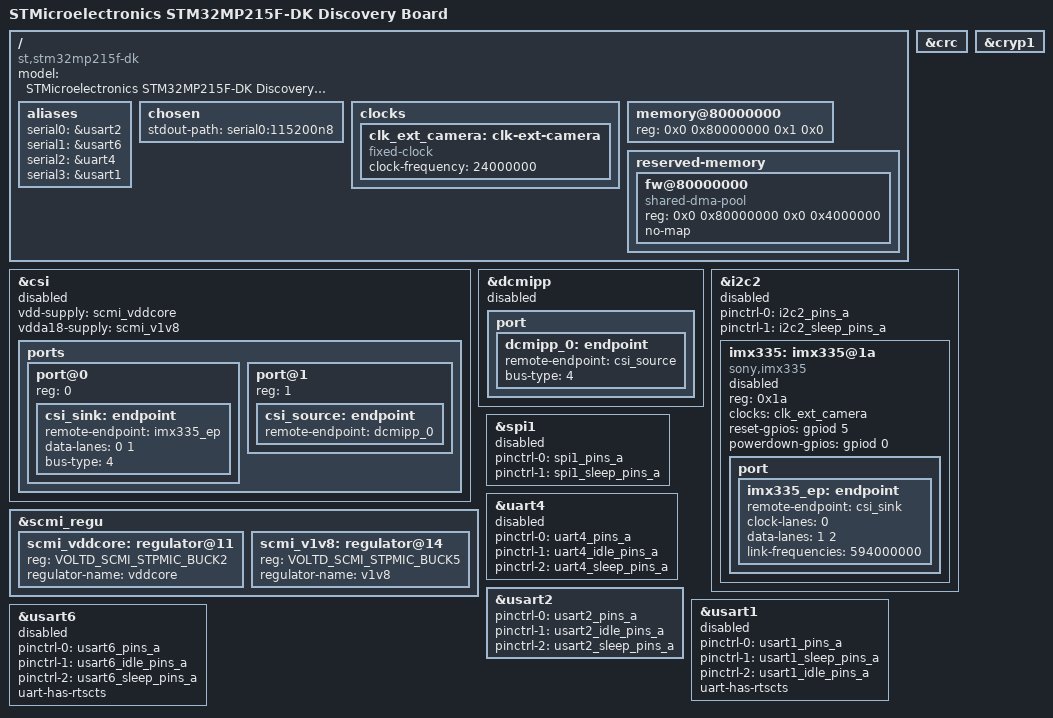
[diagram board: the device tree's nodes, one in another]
// SPDX-License-Identifier: (GPL-2.0-only OR BSD-3-Clause)
/*
 * Copyright (C) STMicroelectronics 2024 - All Rights Reserved
 * Author: Amelie Delaunay <amelie.delaunay@foss.st.com> for STMicroelectronics.
 */

/dts-v1/;

#include <dt-bindings/gpio/gpio.h>
#include "stm32mp215.dtsi"
#include "stm32mp21xf.dtsi"
#include "stm32mp21-pinctrl.dtsi"
#include "stm32mp21xxan-pinctrl.dtsi"

/ {
	model = "STMicroelectronics STM32MP215F-DK Discovery Board";
	compatible = "st,stm32mp215f-dk", "st,stm32mp215";

	aliases {
		serial0 = &usart2;
		serial1 = &usart6;
		serial2 = &uart4;
		serial3 = &usart1;
	};

	chosen {
		stdout-path = "serial0:115200n8";
	};

	clocks {
		clk_ext_camera: clk-ext-camera {
			#clock-cells = <0>;
			compatible = "fixed-clock";
			clock-frequency = <24000000>;
		};
	};

	memory@80000000 {
		device_type = "memory";
		reg = <0x0 0x80000000 0x1 0x0>;
	};

	reserved-memory {
		#address-cells = <2>;
		#size-cells = <2>;
		ranges;

		fw@80000000 {
			compatible = "shared-dma-pool";
			reg = <0x0 0x80000000 0x0 0x4000000>;
			no-map;
		};
	};
};

&crc {
	status = "okay";
};

&cryp1 {
	status = "okay";
};

&csi {
	vdd-supply =  <&scmi_vddcore>;
	vdda18-supply = <&scmi_v1v8>;
	status = "disabled";
	ports {
		#address-cells = <1>;
		#size-cells = <0>;
		port@0 {
			reg = <0>;
			csi_sink: endpoint {
				remote-endpoint = <&imx335_ep>;
				data-lanes = <0 1>;
				bus-type = <4>;
			};
		};
		port@1 {
			reg = <1>;
			csi_source: endpoint {
				remote-endpoint = <&dcmipp_0>;
			};
		};
	};
};

&dcmipp {
	status = "disabled";
	port {
		dcmipp_0: endpoint {
			remote-endpoint = <&csi_source>;
			bus-type = <4>;
		};
	};
};

&i2c2 {
	pinctrl-names = "default", "sleep";
	pinctrl-0 = <&i2c2_pins_a>;
	pinctrl-1 = <&i2c2_sleep_pins_a>;
	status = "disabled";

	imx335: imx335@1a {
		compatible = "sony,imx335";
		reg = <0x1a>;
		clocks = <&clk_ext_camera>;
		reset-gpios = <&gpiod 5 (GPIO_ACTIVE_HIGH | GPIO_PUSH_PULL)>;
		powerdown-gpios = <&gpiod 0 (GPIO_ACTIVE_HIGH | GPIO_PUSH_PULL)>;
		status = "disabled";

		port {
			imx335_ep: endpoint {
				remote-endpoint = <&csi_sink>;
				clock-lanes = <0>;
				data-lanes = <1 2>;
				link-frequencies = /bits/ 64 <594000000>;
			};
		};
	};
};

&scmi_regu {
	scmi_vddcore: regulator@11  {
		reg = <VOLTD_SCMI_STPMIC_BUCK2>;
		regulator-name = "vddcore";
	};
	scmi_v1v8: regulator@14  {
		reg = <VOLTD_SCMI_STPMIC_BUCK5>;
		regulator-name = "v1v8";
	};
};

&spi1 {
	pinctrl-names = "default", "sleep";
	pinctrl-0 = <&spi1_pins_a>;
	pinctrl-1 = <&spi1_sleep_pins_a>;
	status = "disabled";
};

&uart4 {
	pinctrl-names = "default", "idle", "sleep";
	pinctrl-0 = <&uart4_pins_a>;
	pinctrl-1 = <&uart4_idle_pins_a>;
	pinctrl-2 = <&uart4_sleep_pins_a>;
	/delete-property/dmas;
	/delete-property/dma-names;
	status = "disabled";
};

&usart2 {
	pinctrl-names = "default", "idle", "sleep";
	pinctrl-0 = <&usart2_pins_a>;
	pinctrl-1 = <&usart2_idle_pins_a>;
	pinctrl-2 = <&usart2_sleep_pins_a>;
	/delete-property/dmas;
	/delete-property/dma-names;
	status = "okay";
};

/* Bluetooth */
&usart1 {
	pinctrl-names = "default", "sleep", "idle";
	pinctrl-0 = <&usart1_pins_a>;
	pinctrl-1 = <&usart1_sleep_pins_a>;
	pinctrl-2 = <&usart1_idle_pins_a>;
	uart-has-rtscts;
	status = "disabled";
};

&usart6 {
	pinctrl-names = "default", "idle", "sleep";
	pinctrl-0 = <&usart6_pins_a>;
	pinctrl-1 = <&usart6_idle_pins_a>;
	pinctrl-2 = <&usart6_sleep_pins_a>;
	uart-has-rtscts;
	status = "disabled";
};
